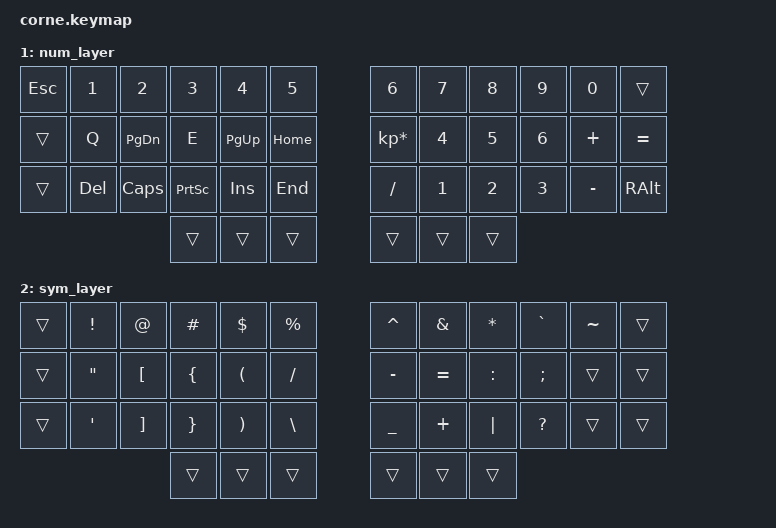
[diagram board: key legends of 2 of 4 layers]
// Copyright (c) 2022 The ZMK Contributors
// SPDX-License-Identifier: MIT

#include <behaviors.dtsi>
#include <dt-bindings/zmk/keys.h>
#include <dt-bindings/zmk/bt.h>
#include <dt-bindings/zmk/outputs.h>

// Home row mods macro
#define HRML(k2,k3,k4) &ht LALT k2  &ht LGUI k3  &ht LCTRL k4
#define HRMR(k1,k2,k3) &ht RCTRL k1  &ht RGUI k2  &ht RALT k3


#define DEF 0
#define NUM 1
#define SYM 2
#define FUN 3

  / {

    macros {
        work_email: work_email {
            compaitble = "zmk,behavior-macro";
            wait-ms = <40>;
            tap-ms = <40>;
            #binding-cells = <0>;
            bindings
            = <&kp K &kp O &kp A &kp L &kp L &kp I &kp S &kp O &kp N>
              ,<&kp AT>
              ,<&kp V &kp R &kp I &kp C &kp A &kp R &kp E &kp S> 
              ,<&kp DOT>
              ,<&kp C &kp O &kp M>;
        };
        home_email: home_email {
            compaitble = "zmk,behavior-macro";
            wait-ms = <40>;
            tap-ms = <40>;
            #binding-cells = <0>;
            bindings
            = <&kp K &kp O &kp R &kp Y &kp R &kp A &kp L &kp L &kp I &kp S &kp O &kp N>
              ,<&kp AT>
              ,<&kp G &kp M &kp A &kp I &kp L>
              ,<&kp DOT>
              ,<&kp C &kp O &kp M>;
        };
        PARM: PARM {
            compaitble = "zmk,behavior-macro";
            wait-ms = <40>;
            tap-ms = <40>;
            #binding-cells = <0>;
            bindings
            = <&kp LPAR &kp RPAR>
              ,<&kp LEFT>;
        };
    };
    behaviors {
        ht: hold_tap {
            label = "hold_tap";
            compatible = "zmk,behavior-hold-tap";
            #binding-cells = <2>;
            flavor = "tap-preferred";
            tapping-term-ms = <220>;
            quick-tap-ms = <150>;
            global-quick-tap;
            bindings = <&kp>, <&kp>;
        };
    };

    conditional_layers {
        compatible = "zmk,conditional-layers";
        tri_layer {
            if-layers = <1 2>;
            then-layer = <3>;
        };
    };

    keymap {
        compatible = "zmk,keymap";
        default_layer {
            bindings = <
        //╭──────────┬──────────┬──────────┬──────────┬──────────┬──────────╮   ╭──────────┬──────────┬──────────┬──────────┬──────────┬──────────╮
        //│  TAB     │  Q       │  W       │  E       │  R       │  T       |   │  Y       │  U       │  I       │  O       │  P       │ BACKSPACE|
            &kp TAB     &kp Q      &kp W      &kp E      &kp R      &kp T          &kp Y      &kp U      &kp I      &kp O      &kp P     &kp BSPC
        //├──────────┼──────────┼──────────┼──────────┼──────────┤──────────┤   ├──────────├──────────┼──────────┼──────────┼──────────┼──────────┤
        //│  CTRL    │  A       │  S       │  D       │  F       │   G      |   │  H       │  J       │  K       │  L       │ '; :'    │  '' ""   |
            &kp LCTRL   &kp A      HRML(S,         D,         F)     &kp G         &kp H      HRMR(J,        K,           L)  &kp SEMI    &kp SQT
        //├──────────┼──────────┼──────────┼──────────┼──────────┤──────────┤   ├──────────├──────────┼──────────┼──────────┼──────────┼──────────┤
        //│ SHIFT    │  Z       │  X       │  C       │  V       │  B       │   │  N       │  M       │ , <      │ . >      │ / ?      │ SHIFT    |
            &kp LSHIFT  &kp Z      &kp X      &kp C      &kp V      &kp B          &kp N      &kp M      &kp COMMA  &kp DOT   &kp FSLH   &kp RSHIFT           
        //╰──────────┴──────────┴──────────┼──────────┼──────────┤──────────┤   ├──────────├──────────┼──────────┼──────────┴──────────┴──────────╯
        //                                 | CTRL     |  ALT     |  SPACE   |   |  ENTER   | SHIFT    | BACKSPACE|
                                             &kp LCTRL   &lt NUM LALT   &kp SPACE  &kp RET   &kp RSHIFT  &lt SYM BSPC
        //                                 ╰──────────┴──────────┴──────────╯   ╰──────────┴──────────┴──────────╯
            >;
        };

        num_layer {
            bindings = <
        //╭──────────┬──────────┬──────────┬──────────┬──────────┬──────────╮   ╭──────────┬──────────┬──────────┬──────────┬──────────┬──────────╮
        //│  ESCP    │  1       │  2       │  3       │  4       │  5       |   │  6       │  7       │  8       │  9       │  0       │          |
            &kp ESCAPE  &kp N1     &kp N2     &kp N3     &kp N4     &kp N5         &kp N6     &kp N7     &kp N8     &kp N9     &kp N0    &trans
        //├──────────┼──────────┼──────────┼──────────┼──────────┤──────────┤   ├──────────├──────────┼──────────┼──────────┼──────────┼──────────┤
        //│          │  Q       │ PAGE DWN │   E      │ PAGE UP  │   HOME   |   │  *       │  4       │  5       │  6       │ +        │  =       |
            &trans      &kp Q     &kp PG_DN    &kp E    &kp PG_UP    &kp HOME   &kp KP_MULTIPLY &kp N4   &kp N5     &kp N6    &kp PLUS    &kp EQUAL
        //├──────────┼──────────┼──────────┼──────────┼──────────┤──────────┤   ├──────────├──────────┼──────────┼──────────┼──────────┼──────────┤
        //│          │  DELETE  │ CapsLock │ PrintSc  │  INSERT  │  END     │   │  /       │  1       │ 2        │  3       │ -        │ ALT      |
            &trans      &kp DEL   &kp CAPS   &kp PSCRN   &kp INS    &kp END        &kp FSLH   &kp N1     &kp N2    &kp N3     &kp MINUS  &kp RALT           
        //╰──────────┴──────────┴──────────┼──────────┼──────────┤──────────┤   ├──────────├──────────┼──────────┼──────────┴──────────┴──────────╯
        //                                 |          |          |          |   |          |          |          |
                                             &trans      &trans     &trans         &trans     &trans     &trans   
        //                                 ╰──────────┴──────────┴──────────╯   ╰──────────┴──────────┴──────────╯
            >;
        };

        sym_layer {
            bindings = <
        //╭──────────┬──────────┬──────────┬──────────┬──────────┬──────────╮   ╭──────────┬──────────┬──────────┬──────────┬──────────┬──────────╮
        //│          │  !       │  @       │  '#'     │  $       │  %       │   │ ^        │ &        │ *        │ `        │ ~        │          |
            &trans      &kp EXCL   &kp AT     &kp HASH   &kp DLLR   &kp PRCNT     &kp CARET  &kp AMPS   &kp ASTRK  &kp GRAVE  &kp TILDE  &trans
        //├──────────┼──────────┼──────────┼──────────┼──────────┤──────────┤   ├──────────├──────────┼──────────┼──────────┼──────────┼──────────┤
        //│          │  ""      │  [       │  {       │  (       │  /       │   │  -       │  =       │  :       │  ';'     │          │          |
            &trans      &kp DQT    &kp LBKT   &kp LBRC   &kp LPAR   &kp FSLH       &kp MINUS  &kp EQUAL  &kp COLON  &kp SEMI   &trans     &trans
        //├──────────┼──────────┼──────────┼──────────┼──────────┤──────────┤   ├──────────├──────────┼──────────┼──────────┼──────────┼──────────┤
        //│          │  ''      │  ]       │  }       │  )       │  \       │   │  _       │  +       │  │       │ ?        │          │          |
            &trans      &kp SQT    &kp RBKT   &kp RBRC   &kp RPAR   &kp BSLH       &kp UNDER  &kp PLUS   &kp PIPE  &kp QMARK   &trans    &trans           
        //╰──────────┴──────────┴──────────┼──────────┼──────────┤──────────┤   ├──────────├──────────┼──────────┼──────────┴──────────┴──────────╯
        //                                 |          |          |          |   |          |          |          |
                                             &trans      &trans     &trans         &trans     &trans     &trans   
        //                                 ╰──────────┴──────────┴──────────╯   ╰──────────┴──────────┴──────────╯
            >;
        };

        fun_layer {
            bindings = <
        //╭──────────┬──────────┬──────────┬──────────┬──────────┬──────────╮   ╭──────────┬──────────┬──────────┬──────────┬──────────┬──────────╮
        //│  F1      │  F2      │  F3      │  F4      │  F5      │  F6      │   │  F7      │  F8      │  F9      │  F10     │  F11     │  F12     │
             &kp F1     &kp F2     &kp F3     &kp F4     &kp F5     &kp F6         &kp F7     &kp F8     &kp F9     &kp F10    &kp F11    &kp F12
        //├──────────┼──────────┼──────────┼──────────┼──────────┤──────────┤   ├──────────├──────────┼──────────┼──────────┼──────────┼──────────┤
        //│WINDOWS   │CONTROL   │VOL MUTE  │  VOL UP  │ PREVSONG │          │   │          │  LEFT    │  DOWN    │  UP      │  RIGHT   │          |
           &kp RGUI   &kp RCTRL &kp C_MUTE &kp C_VOL_UP &kp C_PREV  &trans         &trans    &kp LEFT   &kp DOWN   &kp UP     &kp RIGHT   &trans
        //├──────────┼──────────┼──────────┼──────────┼──────────┤──────────┤   ├──────────├──────────┼──────────┼──────────┼──────────┼──────────┤
        //│          │          │PAUSEMUSIC│ VOL DOWN │ NEXTSONG │          │   │  MACRO   │ MACRO    │  MACRO   │          │          │          |
            &trans      &trans   &kp C_PP  &kp C_VOL_DN &kp C_NEXT  &trans   &kp &work_email  &kp &home_email  &kp &PARM     &trans     &trans     &trans
        //╰──────────┴──────────┴──────────┼──────────┼──────────┤──────────┤   ├──────────├──────────┼──────────┼──────────┴──────────┴──────────╯
        //                                 |          |          |          |   |          |          |          |
                                             &trans      &trans     &trans         &trans     &trans     &trans   
        //                                 ╰──────────┴──────────┴──────────╯   ╰──────────┴──────────┴──────────╯
            >;
        };

    };
};
